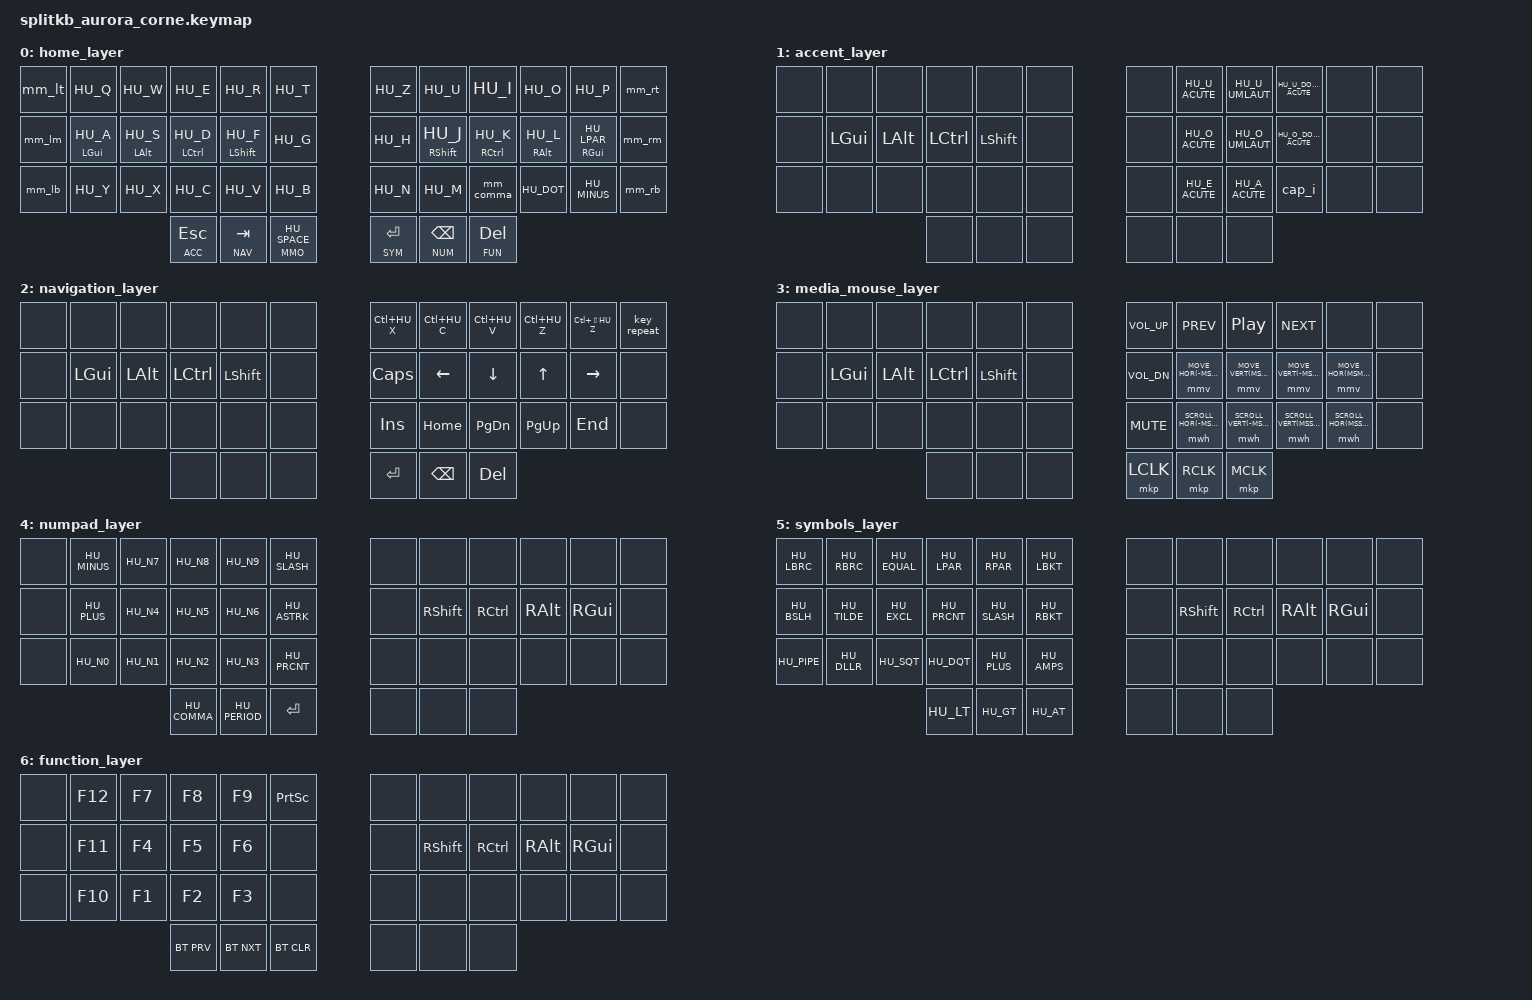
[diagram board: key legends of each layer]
/*
 * Copyright (c) 2020 The ZMK Contributors
 *
 * SPDX-License-Identifier: MIT
 *
 ******************************************************************************************************************************
 *  KEY POSITIONS
 ******************************************************************************************************************************
 *  ╭────────────────────────╮ ╭────────────────────────╮
 *  │ 0   1   2   3   4   5  │ │ 6   7   8   9   10  11 │
 *  │ 12  13  14  15  16  17 │ │ 18  19  19  20  22  23 │
 *  │ 24  25  26  27  28  29 │ │ 30  31  32  33  34  35 │
 *  ╰───────────╮ 36  37  38 │ │ 39  40  41 ╭───────────╯
 *              ╰────────────╯ ╰────────────╯
 *
 *
 ******************************************************************************************************************************
 * Base layer: 0
 ******************************************************************************************************************************
 *  ╭────────┬────────┬────────┬────────┬────────┬────────╮             ╭────────┬────────┬────────┬────────┬────────┬────────╮
 *  │   ?    │  q  Q  │  w  W  │  e  E  │  r  R  │  t  T  │             │  z  Z  │  u  U  │  i  I  │  o  O  │  p  P  │   /    │
 *  │   "    │        │        │        │        │        │             │        │        │        │        │        │   #    │
 *  ├────────┼────────┼────────┼────────┼────────┼────────┤             ├────────┼────────┼────────┼────────┼────────┼────────┤
 *  │   =    │  a  A  │  s  S  │  d  D  │  f  F  │  g  G  │             │  h  H  │  j J   │  k K   │  l L   │   (    │   [    │
 *  │   *    │  Win   │  Alt   │  Ctrl  │  Shift │        │             │        │  Shift │  Ctrl  │  Alt   │  Win   │   '    │
 *  ├────────┼────────┼────────┼────────┼────────┼────────┤             ├────────┼────────┼────────┼────────┼────────┼────────┤
 *  │   <    │  y  Y  │  x  X  │  c  C  │  v  V  │  b  B  │             │  n  N  │  m  M  │   ,    │   .    │   -    │   +    │
 *  │   >    │        │        │        │        │        │             │        │        │   ;    │   :    │   _    │   {    │
 *  ╰────────┴────────┴────────┼────────┼────────┼────────┤             ├────────┼────────┼────────┼────────┴────────┴────────╯
 *                             │  Esc   │  Tab   │ Space  │             │  Enter │  BckS  │  Del   │
 *                             │  Acc   │  Nav   │ Media  │             │  Sym   │  Num   │  Func  │
 *                             ╰────────┴────────┴────────╯             ╰────────┴────────┴────────╯
 *
 ******************************************************************************************************************************
 * Accent layer: 1
 ******************************************************************************************************************************
 *  ╭────────┬────────┬────────┬────────┬────────┬────────╮             ╭────────┬────────┬────────┬────────┬────────┬────────╮
 *  │        │        │        │        │        │        │             │        │  ú  Ú  │  ü  Ü  │  ű  Ű  │        │        │
 *  │        │        │        │        │        │        │             │        │        │        │        │        │        │
 *  ├────────┼────────┼────────┼────────┼────────┼────────┤             ├────────┼────────┼────────┼────────┼────────┼────────┤
 *  │        │  Win   │  Alt   │  Ctrl  │  Shift │        │             │        │  ó  Ó  │  ö  Ö  │  ő  Ő  │        │        │
 *  │        │        │        │        │        │        │             │        │        │        │        │        │        │
 *  ├────────┼────────┼────────┼────────┼────────┼────────┤             ├────────┼────────┼────────┼────────┼────────┼────────┤
 *  │        │        │        │        │        │        │             │        │  é  É  │  á  Á  │  í  Í  │        │        │
 *  │        │        │        │        │        │        │             │        │        │        │        │        │        │
 *  ╰────────┴────────┴────────┼────────┼────────┼────────┤             ├────────┼────────┼────────┼────────┴────────┴────────╯
 *                             │        │        │        │             │        │        │        │
 *                             │        │        │        │             │        │        │        │
 *                             ╰────────┴────────┴────────╯             ╰────────┴────────┴────────╯
 *
 ******************************************************************************************************************************
 * Navigation layer: 2
 ******************************************************************************************************************************
 *  ╭────────┬────────┬────────┬────────┬────────┬────────╮             ╭────────┬────────┬────────┬────────┬────────┬────────╮
 *  │        │        │        │        │        │        │             │  Cut   │  Copy  │  Paste │  Undo  │  Redo  │ Repeat │
 *  │        │        │        │        │        │        │             │        │        │        │        │        │        │
 *  ├────────┼────────┼────────┼────────┼────────┼────────┤             ├────────┼────────┼────────┼────────┼────────┼────────┤
 *  │        │  Win   │  Alt   │  Ctrl  │ Shift  │        │             │  Caps  │  Left  │  Down  │   Up   │  Right │        │
 *  │        │        │        │        │        │        │             │        │        │        │        │        │        │
 *  ├────────┼────────┼────────┼────────┼────────┼────────┤             ├────────┼────────┼────────┼────────┼────────┼────────┤
 *  │        │        │        │        │        │        │             │ Insert │  Home  │ PgDown │  PgUp  │  End   │        │
 *  │        │        │        │        │        │        │             │        │        │        │        │        │        │
 *  ╰────────┴────────┴────────┼────────┼────────┼────────┤             ├────────┼────────┼────────┼────────┴────────┴────────╯
 *                             │        │        │        │             │  Enter │  BckS  │  Del   │
 *                             │        │        │        │             │        │        │        │
 *                             ╰────────┴────────┴────────╯             ╰────────┴────────┴────────╯
 *
 ******************************************************************************************************************************
 * Media/Mouse layer: 3
 ******************************************************************************************************************************
 *  ╭────────┬────────┬────────┬────────┬────────┬────────╮             ╭────────┬────────┬────────┬────────┬────────┬────────╮
 *  │        │        │        │        │        │        │             │  V Up  │  Prev  │  Play  │  Next  │        │        │
 *  │        │        │        │        │        │        │             │        │        │        │        │        │        │
 *  ├────────┼────────┼────────┼────────┼────────┼────────┤             ├────────┼────────┼────────┼────────┼────────┼────────┤
 *  │        │  Win   │  Alt   │  Ctrl  │ Shift  │        │             │  V Dn  │ Ms Lft │ Ms Dwn │ Ms Up  │ Ms Rght│ Brg Up │
 *  │        │        │        │        │        │        │             │        │        │        │        │        │        │
 *  ├────────┼────────┼────────┼────────┼────────┼────────┤             ├────────┼────────┼────────┼────────┼────────┼────────┤
 *  │        │        │        │        │        │        │             │  Mute  │ Scrl L │ Scrl D │ Scrl U │ Scrl R │ Brg Dwn│
 *  │        │        │        │        │        │        │             │        │        │        │        │        │        │
 *  ╰────────┴────────┴────────┼────────┼────────┼────────┤             ├────────┼────────┼────────┼────────┴────────┴────────╯
 *                             │        │        │        │             │  MB L  │  MB R  │  MB M  │
 *                             │        │        │        │             │        │        │        │
 *                             ╰────────┴────────┴────────╯             ╰────────┴────────┴────────╯
 *
 ******************************************************************************************************************************
 * Numpad layer: 4
 ******************************************************************************************************************************
 *  ╭────────┬────────┬────────┬────────┬────────┬────────╮             ╭────────┬────────┬────────┬────────┬────────┬────────╮
 *  │        │   -    │   7    │   8    │   9    │   /    │             │        │        │        │        │        │        │
 *  │        │        │        │        │        │        │             │        │        │        │        │        │        │
 *  ├────────┼────────┼────────┼────────┼────────┼────────┤             ├────────┼────────┼────────┼────────┼────────┼────────┤
 *  │        │   +    │   4    │   5    │   6    │   *    │             │        │  Shift │  Ctrl  │  Alt   │  Win   │        │
 *  │        │        │        │        │        │        │             │        │        │        │        │        │        │
 *  ├────────┼────────┼────────┼────────┼────────┼────────┤             ├────────┼────────┼────────┼────────┼────────┼────────┤
 *  │        │   0    │   1    │   2    │   3    │   %    │             │        │        │        │        │        │        │
 *  │        │        │        │        │        │        │             │        │        │        │        │        │        │
 *  ╰────────┴────────┴────────┼────────┼────────┼────────┤             ├────────┼────────┼────────┼────────┴────────┴────────╯
 *                             │   ,    │   .    │  Enter │             │        │        │        │
 *                             │        │        │        │             │        │        │        │
 *                             ╰────────┴────────┴────────╯             ╰────────┴────────┴────────╯
 *
 ******************************************************************************************************************************
 * Sym layer: 5
 ******************************************************************************************************************************
 *  ╭────────┬────────┬────────┬────────┬────────┬────────╮             ╭────────┬────────┬────────┬────────┬────────┬────────╮
 *  │    {   │   }    │   =    │   (    │    )   │   [    │             │        │        │        │        │        │        │
 *  │        │        │        │        │        │        │             │        │        │        │        │        │        │
 *  ├────────┼────────┼────────┼────────┼────────┼────────┤             ├────────┼────────┼────────┼────────┼────────┼────────┤
 *  │    \   │   ~    │   !    │   %    │    /   │   ]    │             │        │  Shift │  Ctrl  │  Alt   │  Win   │        │
 *  │        │        │        │        │        │        │             │        │        │        │        │        │        │
 *  ├────────┼────────┼────────┼────────┼────────┼────────┤             ├────────┼────────┼────────┼────────┼────────┼────────┤
 *  │    |   │   $    │   '    │   "    │    +   │   &    │             │        │        │        │        │        │        │
 *  │        │        │        │        │        │        │             │        │        │        │        │        │        │
 *  ╰────────┴────────┴────────┼────────┼────────┼────────┤             ├────────┼────────┼────────┼────────┴────────┴────────╯
 *                             │   <    │    >   │   @    │             │        │        │        │
 *                             │        │        │        │             │        │        │        │
 *                             ╰────────┴────────┴────────╯             ╰────────┴────────┴────────╯
 *
 ******************************************************************************************************************************
 * Func layer: 6
 ******************************************************************************************************************************
 *  ╭────────┬────────┬────────┬────────┬────────┬────────╮             ╭────────┬────────┬────────┬────────┬────────┬────────╮
 *  │        │   F12  │   F7   │   F8   │   F9   │ PrtScn │             │        │        │        │        │        │        │
 *  │        │        │        │        │        │        │             │        │        │        │        │        │        │
 *  ├────────┼────────┼────────┼────────┼────────┼────────┤             ├────────┼────────┼────────┼────────┼────────┼────────┤
 *  │        │   F11  │   F4   │   F5   │   F6   │        │             │        │  Shift │  Ctrl  │  Alt   │  Win   │        │
 *  │        │        │        │        │        │        │             │        │        │        │        │        │        │
 *  ├────────┼────────┼────────┼────────┼────────┼────────┤             ├────────┼────────┼────────┼────────┼────────┼────────┤
 *  │        │   F10  │   F1   │   F2   │   F3   │        │             │        │        │        │        │        │        │
 *  │        │        │        │        │        │        │             │        │        │        │        │        │        │
 *  ╰────────┴────────┴────────┼────────┼────────┼────────┤             ├────────┼────────┼────────┼────────┴────────┴────────╯
 *                             │ BltPrv │ BltNxt │ BltClr │             │        │        │        │
 *                             │        │        │        │             │        │        │        │
 *                             ╰────────┴────────┴────────╯             ╰────────┴────────┴────────╯
 *
 */


#include <behaviors.dtsi>
#include <dt-bindings/zmk/keys.h>
#include <dt-bindings/zmk/bt.h>
#include "mouse.dtsi"
#include "keys_hu.h"

#define xxx &none
#define ___ &trans

#define MSMOVE 2500
#define MSSCRL 15

#define HME 0  // Home
#define ACC 1  // Accent
#define NAV 2  // Accent
#define MMO 3  // Media and mouse
#define NUM 4  // Numpad
#define SYM 5  // Symbols
#define FUN 4  // Function

#define QUICK_TAP_MS 175

#define RIGHT_SIDE 6 7 8 9 10 11 18 19 20 21 22 23 30 31 32 33 34 35 39 40 41
#define LEFT_SIDE 0 1 2 3 4 5 12 13 14 15 16 17 24 25 26 27 28 29 36 37 38

#define MOD_MORPH(NAME, KEY, MOD_KEY) \
    mm_##NAME: mm_##NAME { \
        compatible = "zmk,behavior-mod-morph"; \
        label = #NAME; \
        #binding-cells = <0>; \
        bindings = <&kp KEY>, <&kp MOD_KEY>; \
        mods = <(MOD_LSFT|MOD_RSFT)>; \
    };

#define HOME_ROW_MOD(NAME, TRIGGER_POS) \
    hrm_##NAME: hrm_##NAME { \
        compatible = "zmk,behavior-hold-tap"; \
        label = #NAME; \
        #binding-cells = <2>; \
        flavor = "balanced"; \
        tapping-term-ms = <280>; \
        quick-tap-ms = <QUICK_TAP_MS>; \
        global-quick-tap-ms = <150>; \
        bindings = <&kp>, <&kp>; \
        hold-trigger-key-positions = <TRIGGER_POS>; \
        hold-trigger-on-release; \
    };

#define COMBO(NAME, OUTPUT_KEY, TRIGGER_POS) \
    combo_##NAME { \
        timeout-ms = <50>; \
        key-positions = <TRIGGER_POS>; \
        bindings = <OUTPUT_KEY>; \
    };

&mmv {
    time-to-max-speed-ms = <500>;
    acceleration-exponent=<1>;
};

&mwh {
    time-to-max-speed-ms = <2000>;
    acceleration-exponent=<0>;
};

/ {
    behaviors {
        HOME_ROW_MOD(l, RIGHT_SIDE)

        HOME_ROW_MOD(r, LEFT_SIDE)

        MOD_MORPH(lt, HU_QMARK, HU_DQT)
        MOD_MORPH(lm, HU_EQUAL, HU_ASTRK)
        MOD_MORPH(lb, HU_LT, HU_GT)

        MOD_MORPH(rt, KP_SLASH, HU_HASH)
        MOD_MORPH(rm, HU_LBKT, HU_SQT)
        MOD_MORPH(rb, HU_PLUS, HU_LBRC)

        MOD_MORPH(comma, HU_COMMA, HU_SEMI)

        cap_i: capital_i_acute {
            compatible = "zmk,behavior-mod-morph";
            label = "CAPITAL_I_ACUTE_MOD";
            #binding-cells = <0>;
            bindings = <&kp HU_I_ACUTE>, <&kp HU_I_ACUTE_CAP>;
            mods = <(MOD_LSFT)>;
        };
    };

     combos {
        compatible = "zmk,combos";

        COMBO(cut, &kp LC(HU_X), 25 26)
        COMBO(copy, &kp LC(HU_C), 26 27)
        COMBO(paste, &kp LC(HU_V), 27 28)
        COMBO(undo, &kp LC(HU_Z), 6 7)
    };

        keymap {
                compatible = "zmk,keymap";

                home_layer {
                        bindings = <
   &mm_lt  &kp HU_Q          &kp HU_W          &kp HU_E           &kp HU_R           &kp HU_T                   &kp HU_Z     &kp HU_U           &kp HU_I           &kp HU_O          &kp HU_P             &mm_rt
   &mm_lm  &hrm_l LGUI HU_A  &hrm_l LALT HU_S  &hrm_l LCTRL HU_D  &hrm_l LSHFT HU_F  &kp HU_G                   &kp HU_H     &hrm_r RSHFT HU_J  &hrm_r RCTRL HU_K  &hrm_r RALT HU_L  &hrm_r RGUI HU_LPAR  &mm_rm
   &mm_lb  &kp HU_Y          &kp HU_X          &kp HU_C           &kp HU_V           &kp HU_B                   &kp HU_N     &kp HU_M           &mm_comma          &kp HU_DOT        &kp HU_MINUS         &mm_rb
                                               &lt ACC ESC        &lt NAV TAB        &lt MMO HU_SPACE           &lt SYM RET  &lt NUM BSPC       &lt FUN DEL
                        >;
                };

                accent_layer {
                        bindings = <
   xxx  xxx       xxx       xxx        xxx         xxx          xxx  &kp HU_U_ACUTE   &kp HU_U_UMLAUT  &kp HU_U_DOUBLE_ACUTE  xxx  xxx
   xxx  &kp LGUI  &kp LALT  &kp LCTRL  &kp LSHIFT  xxx          xxx  &kp HU_O_ACUTE   &kp HU_O_UMLAUT  &kp HU_O_DOUBLE_ACUTE  xxx  xxx
   xxx  xxx       xxx       xxx        xxx         xxx          xxx  &kp HU_E_ACUTE   &kp HU_A_ACUTE   &cap_i                 xxx  xxx
                            xxx        xxx         xxx          xxx                   xxx              xxx
                        >;
                };

                navigation_layer {
                        bindings = <
   xxx  xxx       xxx       xxx        xxx         xxx          &kp LC(HU_X)  &kp LC(HU_C)  &kp LC(HU_V)  &kp LC(HU_Z)  &kp LC(LS(HU_Z))  &key_repeat
   xxx  &kp LGUI  &kp LALT  &kp LCTRL  &kp LSHIFT  xxx          &kp CAPSLOCK  &kp LEFT      &kp DOWN      &kp UP        &kp RIGHT         xxx
   xxx  xxx       xxx       xxx        xxx         xxx          &kp INSERT    &kp HOME      &kp PG_DN     &kp PG_UP     &kp END           xxx
                            xxx        xxx         xxx          &kp RET       &kp BSPC      &kp DEL
                        >;
                };

                media_mouse_layer {
                        bindings = <
   xxx  xxx       xxx       xxx        xxx         xxx          &kp C_VOL_UP  &kp C_PREV                &kp C_PP                  &kp C_NEXT                xxx                      xxx
   xxx  &kp LGUI  &kp LALT  &kp LCTRL  &kp LSHIFT  xxx          &kp C_VOL_DN  &mmv MOVE_HOR(-MSMOVE)    &mmv MOVE_VERT(MSMOVE)    &mmv MOVE_VERT(-MSMOVE)   &mmv MOVE_HOR(MSMOVE)    xxx
   xxx  xxx       xxx       xxx        xxx         xxx          &kp C_MUTE    &mwh SCROLL_HOR(-MSSCRL)  &mwh SCROLL_VERT(-MSSCRL) &mwh SCROLL_VERT(MSSCRL)  &mwh SCROLL_HOR(MSSCRL)  xxx
                            xxx        xxx         xxx          &mkp LCLK     &mkp RCLK                 &mkp MCLK
                        >;
                };

                numpad_layer {
                        bindings = <
   xxx  &kp HU_MINUS  &kp HU_N7  &kp HU_N8     &kp HU_N9      &kp HU_SLASH         xxx  xxx         xxx        xxx       xxx       xxx
   xxx  &kp HU_PLUS   &kp HU_N4  &kp HU_N5     &kp HU_N6      &kp HU_ASTRK         xxx  &kp RSHIFT  &kp RCTRL  &kp RALT  &kp RGUI  xxx
   xxx  &kp HU_N0     &kp HU_N1  &kp HU_N2     &kp HU_N3      &kp HU_PRCNT         xxx  xxx         xxx        xxx       xxx       xxx
                                 &kp HU_COMMA  &kp HU_PERIOD  &kp RET              xxx  xxx         xxx
                        >;
                };

                symbols_layer {
                        bindings = <
   &kp HU_LBRC  &kp HU_RBRC   &kp HU_EQUAL  &kp HU_LPAR   &kp HU_RPAR   &kp HU_LBKT         xxx      xxx         xxx        xxx       xxx       xxx
   &kp HU_BSLH  &kp HU_TILDE  &kp HU_EXCL   &kp HU_PRCNT  &kp HU_SLASH  &kp HU_RBKT         xxx      &kp RSHIFT  &kp RCTRL  &kp RALT  &kp RGUI  xxx
   &kp HU_PIPE  &kp HU_DLLR   &kp HU_SQT    &kp HU_DQT    &kp HU_PLUS   &kp HU_AMPS         xxx      xxx         xxx        xxx       xxx       xxx
                                            &kp HU_LT     &kp HU_GT     &kp HU_AT           xxx      xxx         xxx
                        >;
                };

                function_layer {
                        bindings = <
   xxx          &kp F12       &kp F7       &kp F8        &kp F9         &kp PSCRN          xxx         xxx         xxx        xxx       xxx       xxx
   xxx          &kp F11       &kp F4       &kp F5        &kp F6         xxx                xxx         &kp RSHIFT  &kp RCTRL  &kp RALT  &kp RGUI  xxx
   xxx          &kp F10       &kp F1       &kp F2        &kp F3         xxx                xxx         xxx         xxx        xxx       xxx       xxx
                                           &bt BT_PRV    &bt BT_NXT     &bt BT_CLR         xxx         xxx         xxx
                        >;
                };
            };
   };
